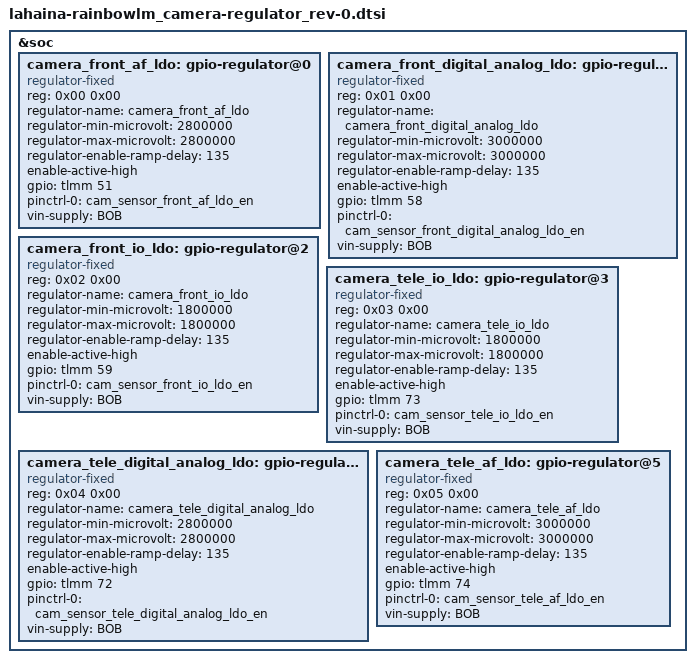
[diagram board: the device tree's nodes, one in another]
#include "lahaina-rainbowlm_camera-pinctrl_rev-0.dtsi"

&soc {
	camera_front_af_ldo: gpio-regulator@0 {
		compatible = "regulator-fixed";
		reg = <0x00 0x00>;
		regulator-name = "camera_front_af_ldo";
		regulator-min-microvolt = <2800000>;
		regulator-max-microvolt = <2800000>;
		regulator-enable-ramp-delay = <135>;
		enable-active-high;
		gpio = <&tlmm 51 0>;
		pinctrl-names = "default";
		pinctrl-0 = <&cam_sensor_front_af_ldo_en>;
		vin-supply = <&BOB>;
	};

	camera_front_digital_analog_ldo: gpio-regulator@1 {
		compatible = "regulator-fixed";
		reg = <0x01 0x00>;
		regulator-name = "camera_front_digital_analog_ldo";
		regulator-min-microvolt = <3000000>;
		regulator-max-microvolt = <3000000>;
		regulator-enable-ramp-delay = <135>;
		enable-active-high;
		gpio = <&tlmm 58 0>;
		pinctrl-names = "default";
		pinctrl-0 = <&cam_sensor_front_digital_analog_ldo_en>;
		vin-supply = <&BOB>;
	};

	camera_front_io_ldo: gpio-regulator@2 {
		compatible = "regulator-fixed";
		reg = <0x02 0x00>;
		regulator-name = "camera_front_io_ldo";
		regulator-min-microvolt = <1800000>;
		regulator-max-microvolt = <1800000>;
		regulator-enable-ramp-delay = <135>;
		enable-active-high;
		gpio = <&tlmm 59 0>;
		pinctrl-names = "default";
		pinctrl-0 = <&cam_sensor_front_io_ldo_en>;
		vin-supply = <&BOB>;
	};

	camera_tele_io_ldo: gpio-regulator@3 {
		compatible = "regulator-fixed";
		reg = <0x03 0x00>;
		regulator-name = "camera_tele_io_ldo";
		regulator-min-microvolt = <1800000>;
		regulator-max-microvolt = <1800000>;
		regulator-enable-ramp-delay = <135>;
		enable-active-high;
		gpio = <&tlmm 73 0>;
		pinctrl-names = "default";
		pinctrl-0 = <&cam_sensor_tele_io_ldo_en>;
		vin-supply = <&BOB>;
	};

	camera_tele_digital_analog_ldo: gpio-regulator@4 {
		compatible = "regulator-fixed";
		reg = <0x04 0x00>;
		regulator-name = "camera_tele_digital_analog_ldo";
		regulator-min-microvolt = <2800000>;
		regulator-max-microvolt = <2800000>;
		regulator-enable-ramp-delay = <135>;
		enable-active-high;
		gpio = <&tlmm 72 0>;
		pinctrl-names = "default";
		pinctrl-0 = <&cam_sensor_tele_digital_analog_ldo_en>;
		vin-supply = <&BOB>;
	};

	camera_tele_af_ldo: gpio-regulator@5 {
		compatible = "regulator-fixed";
		reg = <0x05 0x00>;
		regulator-name = "camera_tele_af_ldo";
		regulator-min-microvolt = <3000000>;
		regulator-max-microvolt = <3000000>;
		regulator-enable-ramp-delay = <135>;
		enable-active-high;
		gpio = <&tlmm 74 0>;
		pinctrl-names = "default";
		pinctrl-0 = <&cam_sensor_tele_af_ldo_en>;
		vin-supply = <&BOB>;
	};
};
